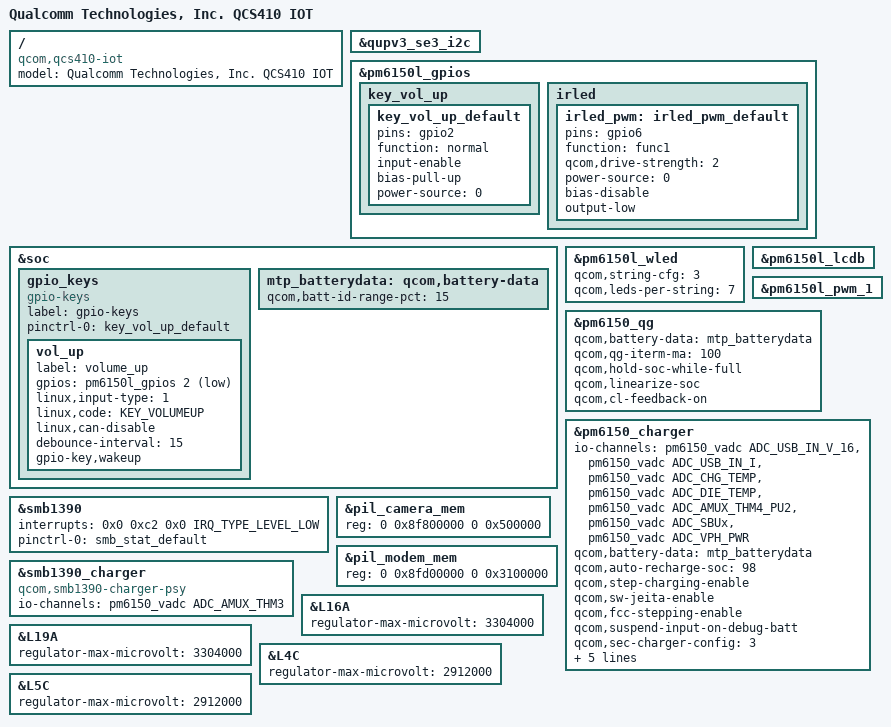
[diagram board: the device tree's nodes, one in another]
/* Copyright (c) 2019, The Linux Foundation. All rights reserved.
 *
 * This program is free software; you can redistribute it and/or modify
 * it under the terms of the GNU General Public License version 2 and
 * only version 2 as published by the Free Software Foundation.
 *
 * This program is distributed in the hope that it will be useful,
 * but WITHOUT ANY WARRANTY; without even the implied warranty of
 * MERCHANTABILITY or FITNESS FOR A PARTICULAR PURPOSE.  See the
 * GNU General Public License for more details.
 */

#include <dt-bindings/gpio/gpio.h>
#include <dt-bindings/iio/qcom,spmi-vadc.h>
#include <dt-bindings/input/input.h>

/ {
	model = "Qualcomm Technologies, Inc. QCS410 IOT";
	compatible = "qcom,qcs410-iot", "qcom,qcs410", "qcom,iot";
};

&qupv3_se3_i2c {
	status = "ok";
	#include "smb1390.dtsi"
};

&pm6150l_gpios {
	key_vol_up {
		key_vol_up_default: key_vol_up_default {
			pins = "gpio2";
			function = "normal";
			input-enable;
			bias-pull-up;
			power-source = <0>;
		};
	};

	irled {
		irled_pwm: irled_pwm_default {
			pins = "gpio6";
			function = "func1";
			qcom,drive-strength = <2>;
			power-source = <0>;
			bias-disable;
			output-low;
		};
	};
};

&soc {
	gpio_keys {
		compatible = "gpio-keys";
		label = "gpio-keys";

		pinctrl-names = "default";
		pinctrl-0 = <&key_vol_up_default>;

		vol_up {
			label = "volume_up";
			gpios = <&pm6150l_gpios 2 GPIO_ACTIVE_LOW>;
			linux,input-type = <1>;
			linux,code = <KEY_VOLUMEUP>;
			linux,can-disable;
			debounce-interval = <15>;
			gpio-key,wakeup;
		};
	};

	mtp_batterydata: qcom,battery-data {
		qcom,batt-id-range-pct = <15>;
		#include "qg-batterydata-alium-3600mah.dtsi"
		#include "qg-batterydata-mlp356477-2800mah.dtsi"
	};
};

&pm6150l_wled {
	qcom,string-cfg= <3>;
	qcom,leds-per-string = <7>;
	status = "ok";
};

&pm6150l_lcdb {
	status = "ok";
};

&pm6150l_pwm_1 {
	status = "okay";
};

&pm6150_qg {
	qcom,battery-data = <&mtp_batterydata>;
	qcom,qg-iterm-ma = <100>;
	qcom,hold-soc-while-full;
	qcom,linearize-soc;
	qcom,cl-feedback-on;
};

&pm6150_charger {
	io-channels = <&pm6150_vadc ADC_USB_IN_V_16>,
		      <&pm6150_vadc ADC_USB_IN_I>,
		      <&pm6150_vadc ADC_CHG_TEMP>,
		      <&pm6150_vadc ADC_DIE_TEMP>,
		      <&pm6150_vadc ADC_AMUX_THM4_PU2>,
		      <&pm6150_vadc ADC_SBUx>,
		      <&pm6150_vadc ADC_VPH_PWR>;
	io-channel-names = "usb_in_voltage",
			   "usb_in_current",
			   "chg_temp",
			   "die_temp",
			   "conn_temp",
			   "sbux_res",
			   "vph_voltage";
	qcom,battery-data = <&mtp_batterydata>;
	qcom,auto-recharge-soc = <98>;
	qcom,step-charging-enable;
	qcom,sw-jeita-enable;
	qcom,fcc-stepping-enable;
	qcom,suspend-input-on-debug-batt;
	qcom,sec-charger-config = <3>;
	qcom,thermal-mitigation = <4200000 3500000 3000000
			2500000 2000000 1500000 1000000 500000>;
	dpdm-supply = <&qusb_phy0>;
	qcom,charger-temp-max = <800>;
	qcom,smb-temp-max = <800>;
};

&smb1390 {
	/delete-property/ interrupts;
	interrupts = <0x0 0xc2 0x0 IRQ_TYPE_LEVEL_LOW>;
	pinctrl-names = "default";
	pinctrl-0 = <&smb_stat_default>;
	status = "ok";
};

&smb1390_charger {
	/delete-property/ compatible;
	compatible = "qcom,smb1390-charger-psy";
	io-channels = <&pm6150_vadc ADC_AMUX_THM3>;
	io-channel-names = "cp_die_temp";
	status = "ok";
};

&pil_camera_mem {
	reg = <0 0x8f800000 0 0x500000>;
};

&pil_modem_mem {
	reg = <0 0x8fd00000 0 0x3100000>;
};

&L16A {
	regulator-max-microvolt = <3304000>;
};

&L19A {
	regulator-max-microvolt = <3304000>;
};

&L4C {
	regulator-max-microvolt = <2912000>;
};

&L5C {
	regulator-max-microvolt = <2912000>;
};
